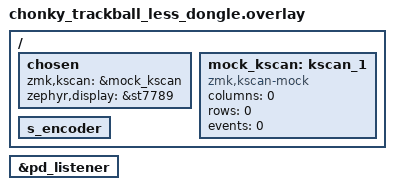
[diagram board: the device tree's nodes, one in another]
#include "chonky_trackball_less.dtsi"

/ {
   chosen {
      zmk,kscan = &mock_kscan;
      zephyr,display = &st7789;
  };

  mock_kscan: kscan_1 {
        compatible = "zmk,kscan-mock";
        columns = <0>;
        rows = <0>;
        events = <0>;
    };

  s_encoder: s_encoder {
        status = "okay";
  };

};

&pd_listener {
    status = "okay";
};

/delete-node/ &default_kscan;   // only required if the dongle uses a
                                // different board than the peripherals
